VERSION "Created by Jacob Geigle"

NS_ :

BS_:

BU_:

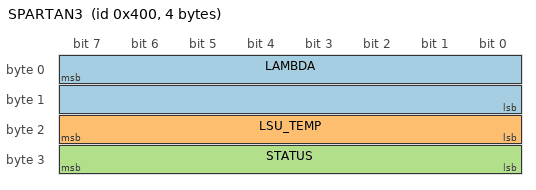
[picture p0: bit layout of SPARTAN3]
BO_ 1024 SPARTAN3: 4 EDL
 SG_ LAMBDA : 7|16@0+ (0.001,0) [0|3.4] "" SPARTAN3
 SG_ LSU_TEMP : 16|8@1+ (10,0) [0|2500] "F" SPARTAN3
 SG_ STATUS : 24|8@1+ (1,0) [0|255] "" SPARTAN3

CM_ BO_ 551 "Spartan3 OEM";
CM_ SG_ 551 LAMBDA "Lambda 1000ths";
CM_ SG_ 551 LSU_TEMP "Sensor Temp Farenheit";
CM_ SG_ 551 STATUS "Status Enum";

VAL_ 1024 STATUS 0 "Reserved" 1 "Waiting to heat up" 2 "Heating up" 3 "Normal operation" 4 "Reserved";
